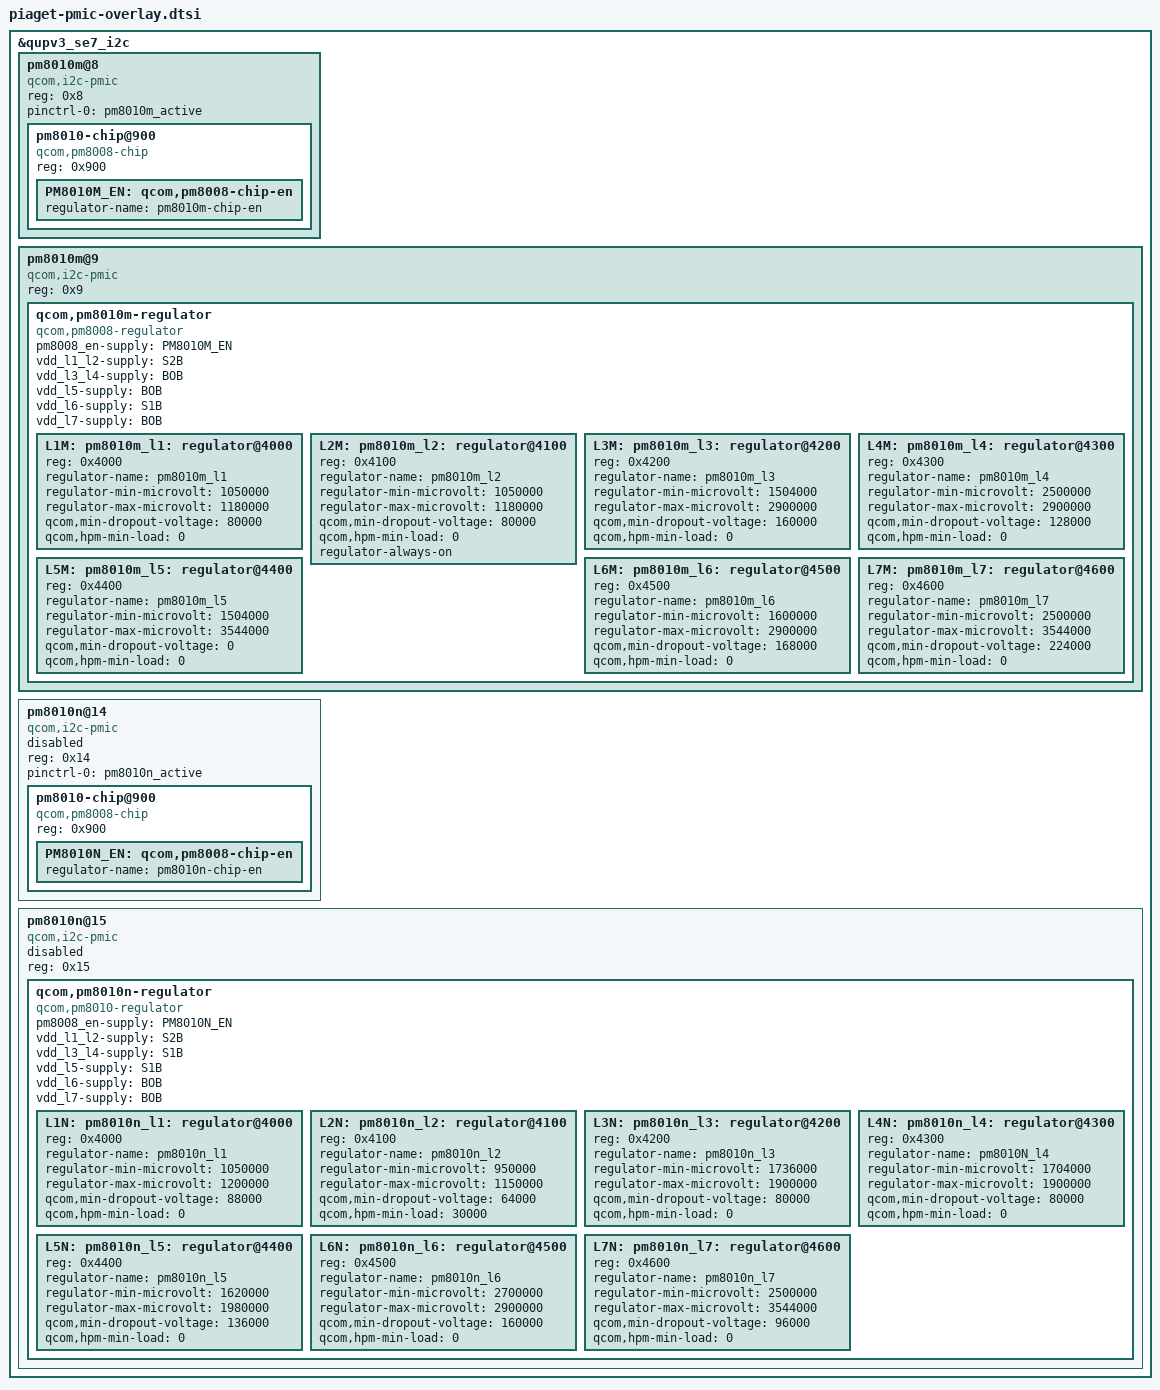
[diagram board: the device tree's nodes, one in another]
&qupv3_se7_i2c {
	#address-cells = <1>;
	#size-cells = <0>;
	status = "ok";

	pm8010m@8 {
		compatible = "qcom,i2c-pmic";
		reg = <0x8>;
		#address-cells = <1>;
		#size-cells = <0>;

		pinctrl-names = "default";
		pinctrl-0 = <&pm8010m_active>;

		pm8010-chip@900 {
			compatible = "qcom,pm8008-chip";
			reg = <0x900>;

			PM8010M_EN: qcom,pm8008-chip-en {
				regulator-name = "pm8010m-chip-en";
			};
		};
	};

	pm8010m@9 {
		compatible = "qcom,i2c-pmic";
		reg = <0x9>;
		#address-cells = <1>;
		#size-cells = <0>;

		qcom,pm8010m-regulator {
			compatible = "qcom,pm8008-regulator";
			#address-cells = <1>;
			#size-cells = <0>;

			pm8008_en-supply = <&PM8010M_EN>;
			vdd_l1_l2-supply = <&S2B>;
			vdd_l3_l4-supply = <&BOB>;
			vdd_l5-supply = <&BOB>;
			vdd_l6-supply = <&S1B>;
			vdd_l7-supply = <&BOB>;

			L1M: pm8010m_l1: regulator@4000 {
				reg = <0x4000>;
				regulator-name = "pm8010m_l1";
				regulator-min-microvolt = <1050000>;
				regulator-max-microvolt = <1180000>;
				qcom,min-dropout-voltage = <80000>;
				qcom,hpm-min-load = <0>;
			};

			L2M: pm8010m_l2: regulator@4100 {
				reg = <0x4100>;
				regulator-name = "pm8010m_l2";
				regulator-min-microvolt = <1050000>;
				regulator-max-microvolt = <1180000>;
				qcom,min-dropout-voltage = <80000>;
				qcom,hpm-min-load = <0>;
				regulator-always-on;
			};

			L3M: pm8010m_l3: regulator@4200 {
				reg = <0x4200>;
				regulator-name = "pm8010m_l3";
				regulator-min-microvolt = <1504000>;
				regulator-max-microvolt = <2900000>;
				qcom,min-dropout-voltage = <160000>;
				qcom,hpm-min-load = <0>;
			};

			L4M: pm8010m_l4: regulator@4300 {
				reg = <0x4300>;
				regulator-name = "pm8010m_l4";
				regulator-min-microvolt = <2500000>;
				regulator-max-microvolt = <2900000>;
				qcom,min-dropout-voltage = <128000>;
				qcom,hpm-min-load = <0>;
			};

			L5M: pm8010m_l5: regulator@4400 {
				reg = <0x4400>;
				regulator-name = "pm8010m_l5";
				regulator-min-microvolt = <1504000>;
				regulator-max-microvolt = <3544000>;
				qcom,min-dropout-voltage = <0>;
				qcom,hpm-min-load = <0>;
			};

			L6M: pm8010m_l6: regulator@4500 {
				reg = <0x4500>;
				regulator-name = "pm8010m_l6";
				regulator-min-microvolt = <1600000>;
				regulator-max-microvolt = <2900000>;
				qcom,min-dropout-voltage = <168000>;
				qcom,hpm-min-load = <0>;
			};

			L7M: pm8010m_l7: regulator@4600 {
				reg = <0x4600>;
				regulator-name = "pm8010m_l7";
				regulator-min-microvolt = <2500000>;
				regulator-max-microvolt = <3544000>;
				qcom,min-dropout-voltage = <224000>;
				qcom,hpm-min-load = <0>;
			};
		};
	};

	pm8010n@14 {
		compatible = "qcom,i2c-pmic";
		reg = <0x14>;
		#address-cells = <1>;
		#size-cells = <0>;
		status = "disabled";

		pinctrl-names = "default";
		pinctrl-0 = <&pm8010n_active>;

		pm8010-chip@900 {
			compatible = "qcom,pm8008-chip";
			reg = <0x900>;

			PM8010N_EN: qcom,pm8008-chip-en {
				regulator-name = "pm8010n-chip-en";
			};
		};
	};

	pm8010n@15 {
		compatible = "qcom,i2c-pmic";
		reg = <0x15>;
		#address-cells = <1>;
		#size-cells = <0>;
		status = "disabled";

		qcom,pm8010n-regulator {
			compatible = "qcom,pm8010-regulator";
			#address-cells = <1>;
			#size-cells = <0>;

			pm8008_en-supply = <&PM8010N_EN>;
			vdd_l1_l2-supply = <&S2B>;
			vdd_l3_l4-supply = <&S1B>;
			vdd_l5-supply = <&S1B>;
			vdd_l6-supply = <&BOB>;
			vdd_l7-supply = <&BOB>;


			L1N: pm8010n_l1: regulator@4000 {
				reg = <0x4000>;
				regulator-name = "pm8010n_l1";
				regulator-min-microvolt = <1050000>;
				regulator-max-microvolt = <1200000>;
				qcom,min-dropout-voltage = <88000>;
				qcom,hpm-min-load = <0>;
			};

			L2N: pm8010n_l2: regulator@4100 {
				reg = <0x4100>;
				regulator-name = "pm8010n_l2";
				regulator-min-microvolt = <950000>;
				regulator-max-microvolt = <1150000>;
				qcom,min-dropout-voltage = <64000>;
				qcom,hpm-min-load = <30000>;
			};

			L3N: pm8010n_l3: regulator@4200 {
				reg = <0x4200>;
				regulator-name = "pm8010n_l3";
				regulator-min-microvolt = <1736000>;
				regulator-max-microvolt = <1900000>;
				qcom,min-dropout-voltage = <80000>;
				qcom,hpm-min-load = <0>;
			};

			L4N: pm8010n_l4: regulator@4300 {
				reg = <0x4300>;
				regulator-name = "pm8010N_l4";
				regulator-min-microvolt = <1704000>;
				regulator-max-microvolt = <1900000>;
				qcom,min-dropout-voltage = <80000>;
				qcom,hpm-min-load = <0>;
			};

			L5N: pm8010n_l5: regulator@4400 {
				reg = <0x4400>;
				regulator-name = "pm8010n_l5";
				regulator-min-microvolt = <1620000>;
				regulator-max-microvolt = <1980000>;
				qcom,min-dropout-voltage = <136000>;
				qcom,hpm-min-load = <0>;
			};

			L6N: pm8010n_l6: regulator@4500 {
				reg = <0x4500>;
				regulator-name = "pm8010n_l6";
				regulator-min-microvolt = <2700000>;
				regulator-max-microvolt = <2900000>;
				qcom,min-dropout-voltage = <160000>;
				qcom,hpm-min-load = <0>;
			};

			L7N: pm8010n_l7: regulator@4600 {
				reg = <0x4600>;
				regulator-name = "pm8010n_l7";
				regulator-min-microvolt = <2500000>;
				regulator-max-microvolt = <3544000>;
				qcom,min-dropout-voltage = <96000>;
				qcom,hpm-min-load = <0>;
			};
		};
	};
};
